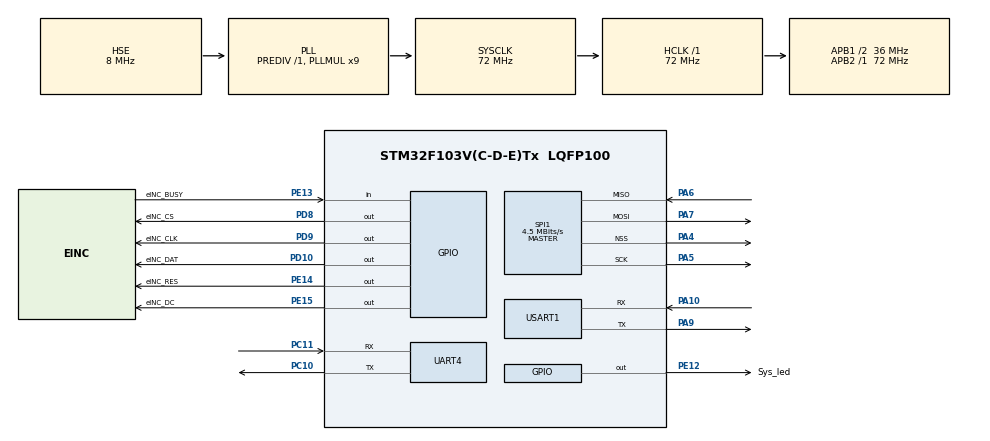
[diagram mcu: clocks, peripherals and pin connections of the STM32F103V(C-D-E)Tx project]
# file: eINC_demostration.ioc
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FREERTOS.BinarySemaphores01=myBinarySem01,Dynamic,NULL
FREERTOS.Mutexes01=myMutex01,Dynamic,NULL
FREERTOS.Tasks01=defaultTask,0,128,StartDefaultTask,Default,NULL,Dynamic,NULL,NULL;myTask02,-3,512,StartTask02,Default,NULL,Dynamic,NULL,NULL;myTask03,-3,128,StartTask03,Default,NULL,Dynamic,NULL,NULL;myTask04,-3,128,StartTask04,Default,NULL,Dynamic,NULL,NULL
FREERTOS.configTOTAL_HEAP_SIZE=8000
IWDG.Prescaler=IWDG_PRESCALER_64
Mcu.Family=STM32F1
Mcu.Name=STM32F103V(C-D-E)Tx
Mcu.Package=LQFP100
NVIC.PriorityGroup=NVIC_PRIORITYGROUP_4
NVIC.SPI1_IRQn=true\:5\:0\:false\:false\:true\:true\:true\:true
NVIC.TIM1_UP_IRQn=true\:0\:0\:false\:false\:true\:false\:false\:true
NVIC.TIM2_IRQn=true\:5\:0\:false\:false\:true\:true\:true\:true
NVIC.TimeBase=TIM1_UP_IRQn
NVIC.TimeBaseIP=TIM1
NVIC.USART1_IRQn=true\:5\:0\:false\:false\:true\:true\:true\:true
OSC_IN.Mode=HSE-External-Oscillator
OSC_IN.Signal=RCC_OSC_IN
OSC_OUT.Mode=HSE-External-Oscillator
OSC_OUT.Signal=RCC_OSC_OUT
PA10.Mode=Asynchronous
PA10.Signal=USART1_RX
PA13.Mode=JTAG_4_pins
PA13.Signal=SYS_JTMS-SWDIO
PA14.Mode=JTAG_4_pins
PA14.Signal=SYS_JTCK-SWCLK
PA15.Mode=JTAG_4_pins
PA15.Signal=SYS_JTDI
PA4.Mode=NSS_Signal_Hard_Output
PA4.Signal=SPI1_NSS
PA5.Mode=Full_Duplex_Master
PA5.Signal=SPI1_SCK
PA6.Mode=Full_Duplex_Master
PA6.Signal=SPI1_MISO
PA7.Mode=Full_Duplex_Master
PA7.Signal=SPI1_MOSI
PA9.Mode=Asynchronous
PA9.Signal=USART1_TX
PB3.Mode=JTAG_4_pins
PB3.Signal=SYS_JTDO-TRACESWO
PC10.Mode=Asynchronous
PC10.Signal=UART4_TX
PC11.Mode=Asynchronous
PC11.Signal=UART4_RX
PC14-OSC32_IN.Mode=LSE-External-Oscillator
PC14-OSC32_IN.Signal=RCC_OSC32_IN
PC15-OSC32_OUT.Mode=LSE-External-Oscillator
PC15-OSC32_OUT.Signal=RCC_OSC32_OUT
PD10.GPIO_Label=eINC_DAT
PD10.GPIO_PuPd=GPIO_PULLUP
PD10.PinState=GPIO_PIN_SET
PD10.Signal=GPIO_Output
PD8.GPIO_Label=eINC_CS
PD8.GPIO_PuPd=GPIO_PULLUP
PD8.PinState=GPIO_PIN_SET
PD8.Signal=GPIO_Output
PD9.GPIO_Label=eINC_CLK
PD9.GPIO_PuPd=GPIO_PULLUP
PD9.PinState=GPIO_PIN_SET
PD9.Signal=GPIO_Output
PE12.GPIO_Label=Sys_led
PE12.GPIO_ModeDefaultOutputPP=GPIO_MODE_OUTPUT_OD
PE12.PinState=GPIO_PIN_SET
PE12.Signal=GPIO_Output
PE13.GPIO_Label=eINC_BUSY
PE13.Signal=GPIO_Input
PE14.GPIO_Label=eINC_RES
PE14.GPIO_PuPd=GPIO_PULLUP
PE14.PinState=GPIO_PIN_SET
PE14.Signal=GPIO_Output
PE15.GPIO_Label=eINC_DC
PE15.GPIO_PuPd=GPIO_PULLUP
PE15.PinState=GPIO_PIN_SET
PE15.Signal=GPIO_Output
ProjectManager.HeapSize=0x200
ProjectManager.StackSize=0x400
ProjectManager.TargetToolchain=MDK-ARM V5
RCC.AHBFreq_Value=72000000
RCC.APB1CLKDivider=RCC_HCLK_DIV2
RCC.APB1Freq_Value=36000000
RCC.APB1TimFreq_Value=72000000
RCC.APB2Freq_Value=72000000
RCC.APB2TimFreq_Value=72000000
RCC.HCLKFreq_Value=72000000
RCC.PLLMUL=RCC_PLL_MUL9
RCC.PLLSourceVirtual=RCC_PLLSOURCE_HSE
RCC.RTCClockSelection=RCC_RTCCLKSOURCE_LSE
RCC.SYSCLKFreq_VALUE=72000000
RCC.SYSCLKSource=RCC_SYSCLKSOURCE_PLLCLK
RCC.USBFreq_Value=72000000
SPI1.BaudRatePrescaler=SPI_BAUDRATEPRESCALER_16
SPI1.CalculateBaudRate=4.5 MBits/s
SPI1.Direction=SPI_DIRECTION_2LINES
SPI1.Mode=SPI_MODE_MASTER
SPI1.VirtualNSS=VM_NSSHARD
SPI1.VirtualType=VM_MASTER
TIM2.AutoReloadPreload=TIM_AUTORELOAD_PRELOAD_ENABLE
TIM2.ClockDivision=TIM_CLOCKDIVISION_DIV4
TIM2.CounterMode=TIM_COUNTERMODE_DOWN
TIM2.Prescaler=18000-1
UART4.VirtualMode=Asynchronous
USART1.VirtualMode=VM_ASYNC
VP_CRC_VS_CRC.Mode=CRC_Activate
VP_FREERTOS_VS_CMSIS_V1.Mode=CMSIS_V1
VP_IWDG_VS_IWDG.Mode=IWDG_Activate
VP_RTC_VS_RTC_Activate.Mode=RTC_Enabled
VP_SYS_VS_tim1.Mode=TIM1
VP_TIM2_VS_ClockSourceINT.Mode=Internal
VP_TIM2_VS_ClockSourceITR.Mode=TriggerSource_ITR0
VP_TIM2_VS_ControllerModeReset.Mode=Reset Mode
board=custom

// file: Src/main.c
/* USER CODE BEGIN Header */
/**
  ******************************************************************************
  * @file           : main.c
  * @brief          : Main program body
  ******************************************************************************
  * @attention
  *
  * <h2><center>&copy; Copyright (c) 2019 STMicroelectronics.
  * All rights reserved.</center></h2>
  *
  * This software component is licensed by ST under Ultimate Liberty license
  * SLA0044, the "License"; You may not use this file except in compliance with
  * the License. You may obtain a copy of the License at:
  *                             www.st.com/SLA0044
  *
  ******************************************************************************
  */
/* USER CODE END Header */

#include "main.h"
#include "cmsis_os.h"
#include "crc.h"
#include "iwdg.h"
#include "rtc.h"
#include "spi.h"
#include "tim.h"
#include "usart.h"
#include "gpio.h"

/* USER CODE BEGIN Includes */
#include "common.h"
#include "led.h"
/* USER CODE END Includes */

void SystemClock_Config(void);
void MX_FREERTOS_Init(void);

int main(void)
{

  /* MCU Configuration--------------------------------------------------------*/

  /* Reset of all peripherals, Initializes the Flash interface and the Systick. */
  HAL_Init();

  /* Configure the system clock */
  SystemClock_Config();

  /* Initialize all configured peripherals */
  MX_GPIO_Init();
  MX_CRC_Init();
  MX_IWDG_Init();
  MX_RTC_Init();
  MX_SPI1_Init();
  MX_TIM2_Init();
  MX_UART4_Init();
  MX_USART1_UART_Init();
  /* USER CODE BEGIN 2 */
  Debug_printf("Info: Hello world.\n");
  /* USER CODE END 2 */

  /* Call init function for freertos objects (in freertos.c) */
  MX_FREERTOS_Init();

  /* Start scheduler */
  osKernelStart();

  /* We should never get here as control is now taken by the scheduler */

  /* Infinite loop */
  while (1)
  {

  }
}

void SystemClock_Config(void)
{
  RCC_OscInitTypeDef RCC_OscInitStruct = {0};
  RCC_ClkInitTypeDef RCC_ClkInitStruct = {0};
  RCC_PeriphCLKInitTypeDef PeriphClkInit = {0};

  /** Initializes the CPU, AHB and APB busses clocks
  */
  RCC_OscInitStruct.OscillatorType = RCC_OSCILLATORTYPE_LSI|RCC_OSCILLATORTYPE_HSE
                              |RCC_OSCILLATORTYPE_LSE;
  RCC_OscInitStruct.HSEState = RCC_HSE_ON;
  RCC_OscInitStruct.HSEPredivValue = RCC_HSE_PREDIV_DIV1;
  RCC_OscInitStruct.LSEState = RCC_LSE_ON;
  RCC_OscInitStruct.HSIState = RCC_HSI_ON;
  RCC_OscInitStruct.LSIState = RCC_LSI_ON;
  RCC_OscInitStruct.PLL.PLLState = RCC_PLL_ON;
  RCC_OscInitStruct.PLL.PLLSource = RCC_PLLSOURCE_HSE;
  RCC_OscInitStruct.PLL.PLLMUL = RCC_PLL_MUL9;
  if (HAL_RCC_OscConfig(&RCC_OscInitStruct) != HAL_OK)
  {
    Error_Handler();
  }
  /** Initializes the CPU, AHB and APB busses clocks
  */
  RCC_ClkInitStruct.ClockType = RCC_CLOCKTYPE_HCLK|RCC_CLOCKTYPE_SYSCLK
                              |RCC_CLOCKTYPE_PCLK1|RCC_CLOCKTYPE_PCLK2;
  RCC_ClkInitStruct.SYSCLKSource = RCC_SYSCLKSOURCE_PLLCLK;
  RCC_ClkInitStruct.AHBCLKDivider = RCC_SYSCLK_DIV1;
  RCC_ClkInitStruct.APB1CLKDivider = RCC_HCLK_DIV2;
  RCC_ClkInitStruct.APB2CLKDivider = RCC_HCLK_DIV1;

  if (HAL_RCC_ClockConfig(&RCC_ClkInitStruct, FLASH_LATENCY_2) != HAL_OK)
  {
    Error_Handler();
  }
  PeriphClkInit.PeriphClockSelection = RCC_PERIPHCLK_RTC;
  PeriphClkInit.RTCClockSelection = RCC_RTCCLKSOURCE_LSE;
  if (HAL_RCCEx_PeriphCLKConfig(&PeriphClkInit) != HAL_OK)
  {
    Error_Handler();
  }
}

void HAL_TIM_PeriodElapsedCallback(TIM_HandleTypeDef *htim)
{
  /* USER CODE BEGIN Callback 0 */
  led_check();
  /* USER CODE END Callback 0 */
  if (htim->Instance == TIM1) {
    HAL_IncTick();
  }
}

void Error_Handler(void)
{
}

/************************ (C) COPYRIGHT STMicroelectronics *****END OF FILE****/

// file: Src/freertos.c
/* USER CODE BEGIN Header */
/**
  ******************************************************************************
  * File Name          : freertos.c
  * Description        : Code for freertos applications
  ******************************************************************************
  * @attention
  *
  * <h2><center>&copy; Copyright (c) 2019 STMicroelectronics.
  * All rights reserved.</center></h2>
  *
  * This software component is licensed by ST under Ultimate Liberty license
  * SLA0044, the "License"; You may not use this file except in compliance with
  * the License. You may obtain a copy of the License at:
  *                             www.st.com/SLA0044
  *
  ******************************************************************************
  */
/* USER CODE END Header */

#include "FreeRTOS.h"
#include "task.h"
#include "main.h"
#include "cmsis_os.h"

/* USER CODE BEGIN Includes */
#include "common.h"
#include "eInk.h"
#include "led.h"

/* USER CODE END Includes */

osThreadId defaultTaskHandle;
osThreadId myTask02Handle;
osThreadId myTask03Handle;
osThreadId myTask04Handle;
osMutexId myMutex01Handle;
osSemaphoreId myBinarySem01Handle;

void StartDefaultTask(void const * argument);
void StartTask02(void const * argument);
void StartTask03(void const * argument);
void StartTask04(void const * argument);

void MX_FREERTOS_Init(void); /* (MISRA C 2004 rule 8.1) */

void MX_FREERTOS_Init(void) {

  /* Create the mutex(es) */
  /* definition and creation of myMutex01 */
  osMutexDef(myMutex01);
  myMutex01Handle = osMutexCreate(osMutex(myMutex01));

  /* Create the semaphores(s) */
  /* definition and creation of myBinarySem01 */
  osSemaphoreDef(myBinarySem01);
  myBinarySem01Handle = osSemaphoreCreate(osSemaphore(myBinarySem01), 1);

  /* Create the thread(s) */
  /* definition and creation of defaultTask */
  osThreadDef(defaultTask, StartDefaultTask, osPriorityNormal, 0, 128);
  defaultTaskHandle = osThreadCreate(osThread(defaultTask), NULL);

  /* definition and creation of myTask02 */
  osThreadDef(myTask02, StartTask02, osPriorityIdle, 0, 512);
  myTask02Handle = osThreadCreate(osThread(myTask02), NULL);

  /* definition and creation of myTask03 */
  osThreadDef(myTask03, StartTask03, osPriorityIdle, 0, 128);
  myTask03Handle = osThreadCreate(osThread(myTask03), NULL);

  /* definition and creation of myTask04 */
  osThreadDef(myTask04, StartTask04, osPriorityIdle, 0, 128);
  myTask04Handle = osThreadCreate(osThread(myTask04), NULL);

}

void StartDefaultTask(void const * argument)
{

  /* USER CODE BEGIN StartDefaultTask */
  /* Infinite loop */
  for(;;)
  {
#if 0
    Debug_printf("Info: Hello StartDefaultTask.\n");
#endif
    MX_IWDG_Reload();
    osDelay(1000);
  }
  /* USER CODE END StartDefaultTask */
}

/* USER CODE BEGIN Header_StartTask02 */
/**
* @note This task is set for eEINK print temporary.
* @author Washington Ruan
* @date Jun.11th, 2019
*/
/**
* @brief Function implementing the myTask02 thread.
* @param argument: Not used
* @retval None
*/
/* USER CODE END Header_StartTask02 */
void StartTask02(void const * argument)
{
  /* USER CODE BEGIN StartTask02 */
  /* Infinite loop */
  for(;;)
  {
    EPD_Task();
    osDelay(1);
  }
  /* USER CODE END StartTask02 */
}

void StartTask03(void const * argument)
{
  /* USER CODE BEGIN StartTask03 */
  /* Infinite loop */
  for(;;)
  {
    led_routine();
    osDelay(1);
  }
  /* USER CODE END StartTask03 */
}

void StartTask04(void const * argument)
{
  for(;;)
  {
    osDelay(1);
  }
}

/************************ (C) COPYRIGHT STMicroelectronics *****END OF FILE****/
